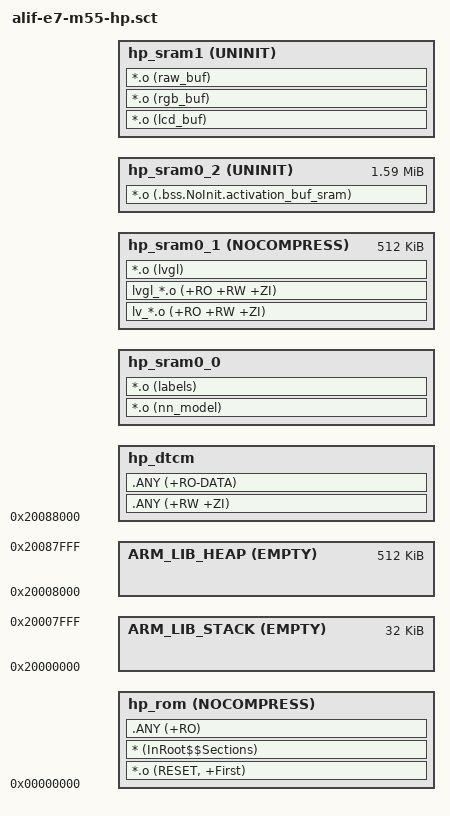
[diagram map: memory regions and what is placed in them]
#! armclang -E --target=arm-arm-none-eabi -mcpu=cortex-m55 -xc
; command above MUST be in first line (no comment above!)
#include "../../device/alif-ensemble/RTE/Device/AE722F80F55D5LS_M55_HP/M55_HP_map.h"

;  SPDX-FileCopyrightText: Copyright 2022-2024 Arm Limited and/or its
;  affiliates <open-source-office@arm.com>
;  SPDX-License-Identifier: Apache-2.0
;
;  Licensed under the Apache License, Version 2.0 (the "License");
;  you may not use this file except in compliance with the License.
;  You may obtain a copy of the License at
;
;      http://www.apache.org/licenses/LICENSE-2.0
;
;  Unless required by applicable law or agreed to in writing, software
;  distributed under the License is distributed on an "AS IS" BASIS,
;  WITHOUT WARRANTIES OR CONDITIONS OF ANY KIND, either express or implied.
;  See the License for the specific language governing permissions and
;  limitations under the License.
; *************************************************************
; ***       Scatter-Loading Description File                ***
; *************************************************************
;

#define __STACK_SIZE            (0x00008000)
#define __HEAP_SIZE             (0x00080000)

#define ROM_BASE                (0x00000000)
#define RAM_BASE                (0x20000000)
#define STACK_BASE              (RAM_BASE)
#define HEAP_BASE               (RAM_BASE + __STACK_SIZE)
#define LCD_BUF_SIZE            (0x00124800)
#define LVGL_SIZE               (0x00080000)

#define RGB_BUFFER_SIZE         (0x00132400) /* ~1.2 MiB of RGB and RAW buffers */
#define ARENA_SIZE              (0x00196400) /* ~1.6 MiB of arena */
#define MODEL_BASE              (SRAM0_BASE + 0x100000)


#define DTCM_DATA_SIZE          (SRAM3_SIZE - __HEAP_SIZE - __STACK_SIZE)

;---------------------------------------------------------
; First load region (ITCM); mapped from SRAM4
;---------------------------------------------------------
LOAD_REGION_0       ROM_BASE                  SRAM2_SIZE
{
    ;-----------------------------------------------------
    ; First part of code mem - 256 kiB
    ;-----------------------------------------------------
    hp_rom         ROM_BASE NOCOMPRESS          SRAM2_SIZE
    {
        *.o (RESET, +First)
        * (InRoot$$Sections)
        .ANY (+RO)
    }

    ;-----------------------------------------------------
    ; Stack - first section in the 256 kiB DTCM (SRAM3)
    ;-----------------------------------------------------
    ARM_LIB_STACK STACK_BASE EMPTY ALIGN 8    __STACK_SIZE
    {}

    ;-----------------------------------------------------
    ; Heap - second section in the 256 kiB DTCM (SRAM3)
    ;-----------------------------------------------------
    ARM_LIB_HEAP  HEAP_BASE  EMPTY ALIGN 8     __HEAP_SIZE
    {}
}

LOAD_REGION_1 (HEAP_BASE+__HEAP_SIZE) ALIGN 8 DTCM_DATA_SIZE
{
    ;-----------------------------------------------------
    ; Remaining DTCM for R/O and R/W data
    ;-----------------------------------------------------
    hp_dtcm (HEAP_BASE+__HEAP_SIZE) ALIGN 8 DTCM_DATA_SIZE
    {
        .ANY (+RW +ZI)
        .ANY (+RO-DATA)
    }
}

;---------------------------------------------------------
; Second load region (SRAM0)
;---------------------------------------------------------
LOAD_REGION_2       MODEL_BASE                  SRAM0_SIZE
{
    ;-----------------------------------------------------
    ; SRAM0 space for nn model and input vectors
    ;-----------------------------------------------------
    hp_sram0_0  MODEL_BASE ALIGN 16             SRAM0_SIZE
    {
        ; nn model
        *.o (nn_model)
        ; labels
        *.o (labels)
    }

    ;-----------------------------------------------------
    ; Second part of SRAM0 used LVGL code and data
    ;-----------------------------------------------------
    hp_sram0_1 +0 ALIGN 4 NOCOMPRESS             LVGL_SIZE
    {
        lv_*.o (+RO +RW +ZI)
        lvgl_*.o (+RO +RW +ZI)
        *.o (lvgl) ; Buffers
    }

    ;-----------------------------------------------------
    ; Third part of SRAM0 used for tensor arena
    ;-----------------------------------------------------
    hp_sram0_2  +0 UNINIT ALIGN 16              ARENA_SIZE
    {
        ; activation buffers a.k.a tensor arena
        *.o (.bss.NoInit.activation_buf_sram)
    }
}

;---------------------------------------------------------
; Second load region (SRAM1)
;---------------------------------------------------------
LOAD_REGION_3   SRAM1_BASE                      SRAM1_SIZE
{
    ;-----------------------------------------------------
    ; LCD buffer has to be at SRAM1 base
    ;-----------------------------------------------------
    hp_sram1        SRAM1_BASE ALIGN 16 UNINIT  SRAM1_SIZE
    {
        *.o (lcd_buf) ; Buffer for the LCD
        *.o (rgb_buf) ; Camera RAW Frame Buffer
        *.o (raw_buf) ; camera Frame Buffer for Bayer to RGB Convertion.
    }

    ;-----------------------------------------------------
    ; Need to investigate why when the buffers are placed
    ; in here separately, the application does not boot
    ; correctly (fails at scatter loading stage).
    ;-----------------------------------------------------
    ;img_buffers (SRAM1_BASE+LCD_BUF_SIZE) ALIGN 16 UNINIT (SRAM1_SIZE-LCD_BUF_SIZE)
    ;{
    ;    *.o (rgb_buf) ; Camera RAW Frame Buffer
    ;    *.o (raw_buf) ; camera Frame Buffer for Bayer to RGB Convertion.
    ;}
}
